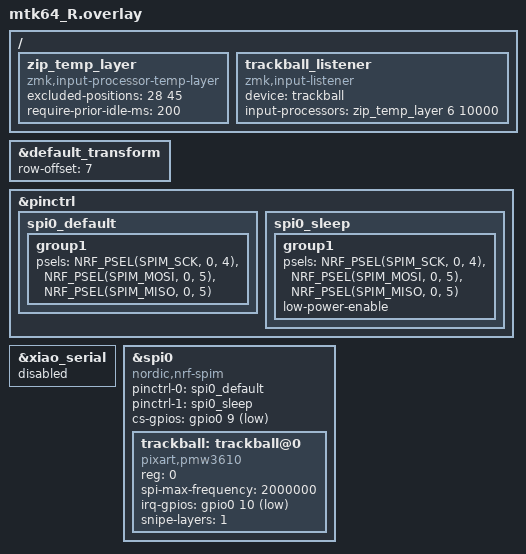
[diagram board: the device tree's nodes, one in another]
#include "mtk64.dtsi"

&default_transform {
    row-offset = <7>;
};

/*
&kscan0 {
    gpiosj
        = <&xiao_d 1 GPIO_ACTIVE_HIGH> 
        , <&xiao_d 2 GPIO_ACTIVE_HIGH> 
        , <&xiao_d 3 GPIO_ACTIVE_HIGH>  
        , <&xiao_d 6 GPIO_ACTIVE_HIGH>
        , <&xiao_d 7 GPIO_ACTIVE_HIGH> 
        , <&xiao_d 8 GPIO_ACTIVE_HIGH> 
        , <&xiao_d 9 GPIO_ACTIVE_HIGH> 	
    ;
};
*/

// / {
//    trackball_listener {
//        compatible = "zmk,input-listener";
//        device = <&trackball>;
//
// 以下、マウスキーを押すまでマウスレイヤーに留まる
// input-processors = <&zip_temp_layer 6 500>;
//
//    };
// };

&pinctrl {
    spi0_default: spi0_default {
        group1 {
            psels = <NRF_PSEL(SPIM_SCK, 0, 4)>,
                <NRF_PSEL(SPIM_MOSI, 0, 5)>,
                <NRF_PSEL(SPIM_MISO, 0, 5)>;
        };
    };

    spi0_sleep: spi0_sleep {
        group1 {
            psels = <NRF_PSEL(SPIM_SCK, 0, 4)>,
                <NRF_PSEL(SPIM_MOSI, 0, 5)>,
                <NRF_PSEL(SPIM_MISO, 0, 5)>;
            low-power-enable;
        };
    };
};

&xiao_serial { status = "disabled"; };

&spi0 {
    status = "okay";
    compatible = "nordic,nrf-spim";
    pinctrl-0 = <&spi0_default>;
    pinctrl-1 = <&spi0_sleep>;
    pinctrl-names = "default", "sleep";
    cs-gpios = <&gpio0 9 GPIO_ACTIVE_LOW>;

    trackball: trackball@0 {
        status = "okay";
        compatible = "pixart,pmw3610";
        reg = <0>;
        spi-max-frequency = <2000000>;
        irq-gpios = <&gpio0 10 (GPIO_ACTIVE_LOW | GPIO_PULL_UP)>;
//       automouse-layer = <6>;
//       scroll-layers = <2>;
         snipe-layers = <1>;
    };
};
// 以下、InputProcessorを使用したオートマウスレイヤーを転記

#include <input/processors.dtsi>

&zip_temp_layer {
    require-prior-idle-ms = <200>;
};

/ {
   /omit-if-no-ref/ zip_temp_layer: zip_temp_layer {
        compatible = "zmk,input-processor-temp-layer";
        #input-processor-cells = <2>;
        excluded-positions = <
//          27 // D
            28 // F
//          33 // J
//          34 // K
            45 // M
//          46 // ,
        >;
    };

    trackball_listener {
        compatible = "zmk,input-listener";
        device = <&trackball>;

        input-processors = <&zip_temp_layer 6 10000>;
    };
};
